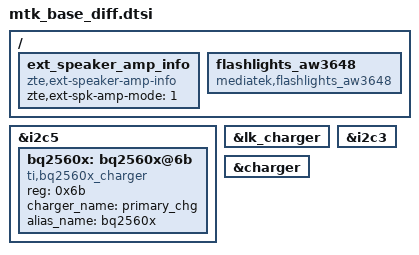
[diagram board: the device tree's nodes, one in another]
/*
 * when you want to delete some nodes or property, modify this dtsi.
 * some diff between mtk and zte scorpio.
 */

#include "../bat_setting/battery_protect_policy_080509200102.dtsi"

/{

	ext_speaker_amp_info {
		status="okay";
		compatible = "zte,ext-speaker-amp-info";
		zte,ext-spk-amp-mode = <1>;
	};

	flashlights_aw3648: flashlights_aw3648 {
		compatible = "mediatek,flashlights_aw3648";
	};
};

&i2c5 {
	bq2560x: bq2560x@6b {
		compatible = "ti,bq2560x_charger";
		status = "okay";
		reg = <0x6b>;

		charger_name = "primary_chg";
		alias_name = "bq2560x";
	};
};

&lk_charger {
	/delete-property/ enable_anime;
	/delete-property/ enable_pe_plus;
	/delete-property/ enable_pd20_reset;
};

&charger {
	/delete-property/ enable_pe_plus;
	/delete-property/ enable_pe_2;
	/delete-property/ enable_pe_3;
	/delete-property/ enable_pe_4;
	/delete-property/ enable_type_c;
	/delete-property/ enable_dynamic_mivr;
};

/ {
	/delete-node/ mt6370_pmu_dts;
};

/ {
	/delete-node/ type_c_port0;
};

&i2c3 {
	/delete-node/ rt9465@4b;
};

